# CY8C5488AXI_LP120 register map
File version: 0.1
Registers are 8-bit, read-write, no defined reset value unless marked. A register's access mark holds for its fields unless they carry their own. Offsets are from the block's base; [hi:lo] are bit positions; {n}, {i} and the like mark numbered series; 'fields as' and 'values as' point back to an identical list.

## Arm_PWM
Base 0x00000000
0x40006422 Arm_PWM_COMPARE_Reg 16-bit — UDB.D0 - Assigned Compare Value
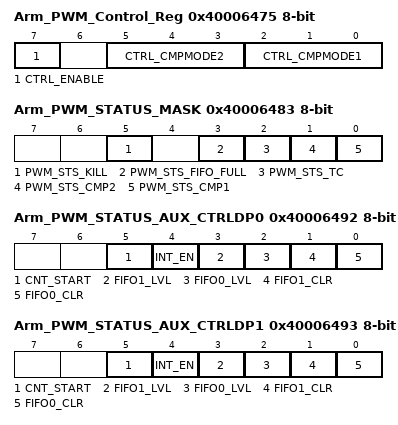
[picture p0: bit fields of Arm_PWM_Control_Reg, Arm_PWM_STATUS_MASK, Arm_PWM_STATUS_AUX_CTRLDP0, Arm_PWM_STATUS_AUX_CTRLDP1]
0x40006475 Arm_PWM_Control_Reg — UDB Control Register - Assigned Control Register Value
  [7] CTRL_ENABLE — Enable the PWM
  [5:3] CTRL_CMPMODE2 — Compare mode 2
  [2:0] CTRL_CMPMODE1 — Compare mode 1
0x40006483 Arm_PWM_STATUS_MASK — UDB Status bits Interrupt Mask Enable Register
  [5] PWM_STS_KILL ro — Enables the Interrupt on Kill
  [3] PWM_STS_FIFO_FULL ro — FIFO Full Status Mask
  [2] PWM_STS_TC ro — Enables the Interrupt on Terminal Count
  [1] PWM_STS_CMP2 ro — Enables the Interrupt on Compare 2
  [0] PWM_STS_CMP1 ro — Enables the Interrupt on Compare 1
0x40006492 Arm_PWM_STATUS_AUX_CTRLDP0 — UDB Auxilliary Control Register
  [5] CNT_START — FIFO0 clear
    0=E_CNT_START0 (Disable counter); 1=E_CNT_START1 (Enable counter)
  [4] INT_EN
    0=E_INT_EN0 (Interrupt disabled); 1=E_INT_EN1 (Interrupt enabled)
  [3] FIFO1_LVL — FIFO level
    0=E_FIFO_LVL_0 (FIFO LVL: input mode: FIFO not full; output mode: FIFO not empty); 1=E_FIFO_LVL_1 (FIFO LVL: input mode: FIFO at least 1/2 empty; output mode: FIFO at least 1/2 full)
  [2] FIFO0_LVL — FIFO level
    values as FIFO1_LVL
  [1] FIFO1_CLR — FIFO1 clear
    0=E_FIFO_CLR_0 (Normal FIFO operation); 1=E_FIFO_CLR_1 (Clear FIFO state)
  [0] FIFO0_CLR — FIFO0 clear
    values as FIFO1_CLR
0x40006493 Arm_PWM_STATUS_AUX_CTRLDP1 — UDB Auxilliary Control Register
  fields as Arm_PWM_STATUS_AUX_CTRLDP0

## USB — USBFS
Base 0x00000000
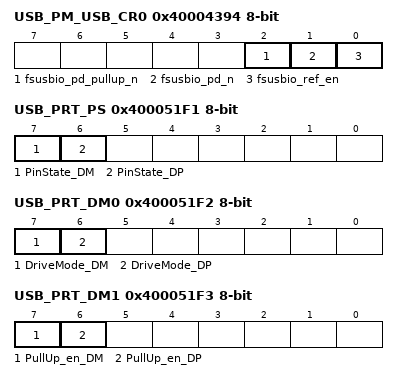
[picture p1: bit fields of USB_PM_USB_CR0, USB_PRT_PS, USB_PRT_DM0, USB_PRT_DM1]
0x40004394 USB_PM_USB_CR0 — USB Power Mode Control Register 0
  [2] fsusbio_pd_pullup_n, [1] fsusbio_pd_n, [0] fsusbio_ref_en
0x400043A5 USB_PM_ACT_CFG — Active Power Mode Configuration Register
0x400043B5 USB_PM_STBY_CFG — Standby Power Mode Configuration Register
0x400051F1 USB_PRT_PS — Port Pin State Register
  [7] PinState_DM ro, [6] PinState_DP ro
0x400051F2 USB_PRT_DM0 — Port Drive Mode Register
  [7] DriveMode_DM, [6] DriveMode_DP
0x400051F3 USB_PRT_DM1 — Port Drive Mode Register
  [7] PullUp_en_DM, [6] PullUp_en_DP
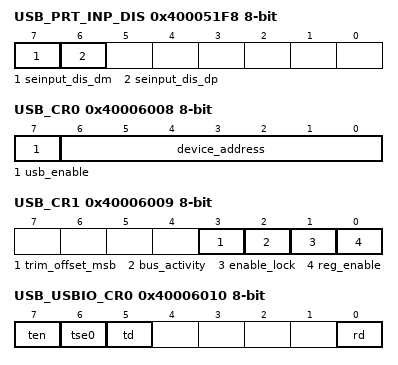
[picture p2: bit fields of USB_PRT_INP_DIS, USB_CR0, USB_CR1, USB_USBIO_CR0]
0x400051F8 USB_PRT_INP_DIS — Input buffer disable override
  [7] seinput_dis_dm, [6] seinput_dis_dp
0x40006000 USB_EP0_DR0 — bmRequestType
0x40006001 USB_EP0_DR1 — bRequest
0x40006002 USB_EP0_DR2 — wValueLo
0x40006003 USB_EP0_DR3 — wValueHi
0x40006004 USB_EP0_DR4 — wIndexLo
0x40006005 USB_EP0_DR5 — wIndexHi
0x40006006 USB_EP0_DR6 — lengthLo
0x40006007 USB_EP0_DR7 — lengthHi
0x40006008 USB_CR0 — USB Control Register 0
  [7] usb_enable, [6:0] device_address ro
0x40006009 USB_CR1 — USB Control Register 1
  [3] trim_offset_msb, [2] bus_activity, [1] enable_lock, [0] reg_enable
{0x40005FFE+0x10*i} USB_SIE_EP{i}_CR0 (i=1..8) — The Endpoint{i} Control Register
0x40006010 USB_USBIO_CR0 — USBIO Control Register 0
  [7] ten, [6] tse0, [5] td, [0] rd ro
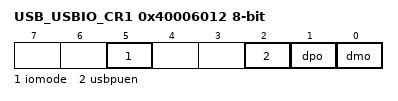
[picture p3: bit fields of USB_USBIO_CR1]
0x40006012 USB_USBIO_CR1 — USBIO Control Register 1
  [5] iomode, [2] usbpuen, [1] dpo ro, [0] dmo ro
0x4000608C USB_BUF_SIZE — Dedicated Endpoint Buffer Size Register
0x4000608E USB_EP_ACTIVE — Endpoint Active Indication Register
0x4000608F USB_EP_TYPE — Endpoint Type (IN/OUT) Indication
0x4000609D USB_USB_CLK_EN — USB Block Clock Enable Register

## MOTOR_L
Base 0x00000000
0x400043A3 MOTOR_L_GLOBAL_ENABLE — PM.ACT.CFG
  [3:0] en_timer — Enable timer/counters.
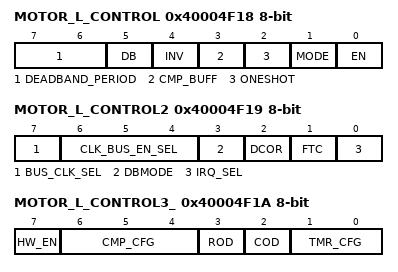
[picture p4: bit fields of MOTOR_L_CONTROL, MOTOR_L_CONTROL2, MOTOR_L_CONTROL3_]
0x40004F18 MOTOR_L_CONTROL — TMRx.CFG0
  [7:6] DEADBAND_PERIOD
  [5] DB — Deadband mode--Deadband phases phi1 and phi2 are outputted on CMP and TC output pins respectively.
    0=Timer (CMP and TC are output.); 1=Deadband (PHI1 (instead of CMP) and PHI2 (instead of TC) are output.)
  [4] INV — Invert sense of TIMEREN signal
  [3] CMP_BUFF — Buffer compare register. Compare register updates only on timer terminal count.
  [2] ONESHOT — Timer stops upon reaching stop condition defined by TMR_CFG bits. Can be restarted by asserting TIMER RESET or disabling and re-enabling block.
  [1] MODE — Mode. (0 = Timer; 1 = Comparator)
    0=Timer mode. CNT/CMP register holds timer count value.; 1=Comparator mode. CNT/CMP register holds comparator threshold value.
  [0] EN — Enables timer/comparator.
0x40004F19 MOTOR_L_CONTROL2 — TMRx.CFG1
  [7] BUS_CLK_SEL — Bus Clock selection.
  [6:4] CLK_BUS_EN_SEL — Digital Global Clock selection.
  [3] DBMODE — Deadband mode (asynchronous/synchronous). CMP output pin is also affected when not in deadband mode (CFG0.DEADBAND).
  [2] DCOR — Disable Clear on Read (DCOR) of Status Register SR0.
  [1] FTC — First Terminal Count (FTC). Setting this bit forces a single pulse on the TC pin when first enabled.
    0=Disable_FTC (Disable the single cycle pulse, which signifies the timer is starting.); 1=Enable_FTC (Enable the single cycle pulse, which signifies the timer is starting.)
  [0] IRQ_SEL — Irq selection. (0 = raw interrupts; 1 = status register interrupts)
0x40004F1A MOTOR_L_CONTROL3_ — TMRx.CFG2
  [7] HW_EN — When set Timer Enable controls counting.
  [6:4] CMP_CFG — Comparator configurations
    0=Equal (Compare Equal); 1=Less_than (Compare Less Than); 2=Less_than_or_equal (Compare Less Than or Equal .); 3=Greater (Compare Greater Than .); 4=Greater_than_or_equal (Compare Greater Than or Equal)
  [3] ROD — Reset On Disable (ROD). Resets internal state of output logic
  [2] COD — Clear On Disable (COD). Clears or gates outputs to zero.
  [1:0] TMR_CFG — Timer configuration (MODE = 0): 000 = Continuous; 001 = Pulsewidth; 010 = Period; 011 = Stop on IRQ
    0=Continuous (Timer runs while EN bit of CFG0 register is set to '1'.); 1=Pulsewidth (Timer runs from positive to negative edge of TIMEREN.); 2=Period (Timer runs from positive to positive edge of TIMEREN.); 3=Irq (Timer runs until IRQ.)
0x40004F1C MOTOR_L_PERIOD — TMRx.PER0 - Assigned Period
0x40004F1E MOTOR_L_COMPARE — TMRx.CNT_CMP0 - Assigned Compare Value
